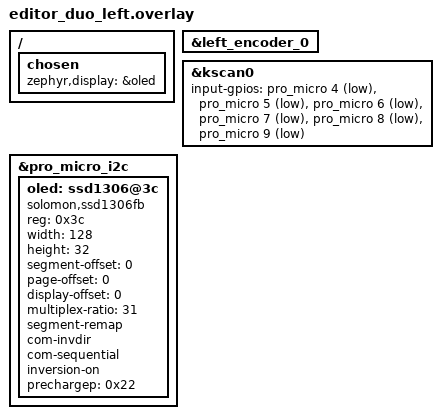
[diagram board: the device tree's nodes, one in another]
/* Generated by ZMK Editor from editor_duo.editor.json. */

#include "editor_duo.dtsi"

&left_encoder_0 {
    status = "okay";
};

&kscan0 {
    input-gpios
        = <&pro_micro  4 (GPIO_ACTIVE_LOW | GPIO_PULL_UP)>
        , <&pro_micro  5 (GPIO_ACTIVE_LOW | GPIO_PULL_UP)>
        , <&pro_micro  6 (GPIO_ACTIVE_LOW | GPIO_PULL_UP)>
        , <&pro_micro  7 (GPIO_ACTIVE_LOW | GPIO_PULL_UP)>
        , <&pro_micro  8 (GPIO_ACTIVE_LOW | GPIO_PULL_UP)>
        , <&pro_micro  9 (GPIO_ACTIVE_LOW | GPIO_PULL_UP)>
        ;
};

&pro_micro_i2c {
    status = "okay";

    oled: ssd1306@3c {
        compatible = "solomon,ssd1306fb";
        reg = <0x3c>;
        width = <128>;
        height = <32>;
        segment-offset = <0>;
        page-offset = <0>;
        display-offset = <0>;
        multiplex-ratio = <31>;
        segment-remap;
        com-invdir;
        com-sequential;
        inversion-on;
        prechargep = <0x22>;
    };
};

/ {
    chosen {
        zephyr,display = &oled;
    };
};
